# MCU_R5FSS0_COMMON0_COMPARE_CFG register map
Vendor: Texas Instruments
Peripheral module from a debugger description file (folder J7_AHP).
Registers are 32-bit, access per field, reset 0x0 unless marked. A register's access mark holds for its fields unless they carry their own. Offsets are as the file gives them; lines under a group give offsets from that group; [hi:lo] are bit positions; {n}, {i} and the like mark numbered series; 'fields as' and 'values as' point back to an identical list; <NAME> marks a mode.

## MCU_R5FSS0_COMMON0_COMPARE_CFG
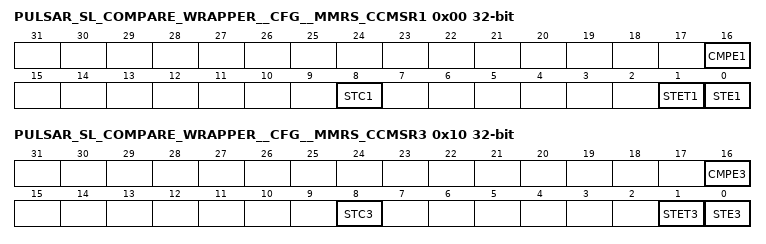
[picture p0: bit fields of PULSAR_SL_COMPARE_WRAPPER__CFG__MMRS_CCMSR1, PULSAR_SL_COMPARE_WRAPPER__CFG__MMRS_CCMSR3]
0x00 PULSAR_SL_COMPARE_WRAPPER__CFG__MMRS_CCMSR1
  [16] CMPE1 rw — This is the CMPE1 field
  [8] STC1 ro — This is the STC1 field
  [1] STET1 ro — This is the STET1 field
  [0] STE1 ro — This is the STE1 field
0x04 PULSAR_SL_COMPARE_WRAPPER__CFG__MMRS_CCMKEYR1
  [3:0] MKEY1 rw — This is the MKEY1 field
0x10 PULSAR_SL_COMPARE_WRAPPER__CFG__MMRS_CCMSR3
  [16] CMPE3 rw — This is the CMPE3 field
  [8] STC3 ro — This is the STC3 field
  [1] STET3 ro — This is the STET3 field
  [0] STE3 ro — This is the STE3 field
0x14 PULSAR_SL_COMPARE_WRAPPER__CFG__MMRS_CCMKEYR3
  [3:0] MKEY3 rw — This is the MKEY3 field
0x18 PULSAR_SL_COMPARE_WRAPPER__CFG__MMRS_CCMPOLCNTRL
  [7:0] POL_INV rw — This is the Polarity Inversion field
